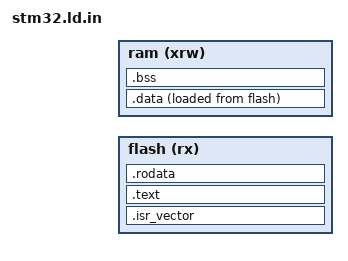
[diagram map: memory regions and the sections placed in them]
ENTRY(_start)

MEMORY
{
  flash (rx) : ORIGIN = @flash_origin@, LENGTH = @flash_kb@K
  ram (xrw) : ORIGIN = @ram_origin@, LENGTH = @ram_kb@K
}

SECTIONS
{
  /* interrupt vector tables */
  /* .isr_vector - ARM core exceptions */
  .isr_vector :
  {
    . = ALIGN(4);
    _sisr_vector = .;
    KEEP(*(.isr_vector))
    KEEP(*(.isr_vector.device))
    . = ALIGN(4);
    _eisr_vector = .;
} >flash

.text :
{
  . = ALIGN(4);
  _stext = .;
  *(.text)
  *(.text*)
  *(.glue_7)
  *(.glue_7t)
  *(.eh_frame)
  KEEP(*(.init))
  KEEP(*(.fini))
  . = ALIGN(4);
  _etext = .;
} >flash

.rodata :
{
  . = ALIGN(4);
  _srodata = .;
  *(.rodata)
  *(.rodata*)
  . = ALIGN(4);
  _erodata = .;
} >flash

.data :
{
  . = ALIGN(4);
  _sdata = .;
  *(.data)
  *(.data*)
  . = ALIGN(4);
  _edata = .;
} >ram AT>flash

__data_start_flash = LOADADDR(.data);
__data_start_ram = ADDR(.data);
__data_size = SIZEOF(.data)

.bss :
{
  . = ALIGN(4);
  _sbss = .;
  *(.bss)
  *(.bss*)
  *(COMMON)
  . = ALIGN(4);
  _ebss = .;
} >ram

/DISCARD/ :
{
  libc.a:* ( * )
  libm.a:* ( * )
  libgcc.a:* ( * )
}

}
